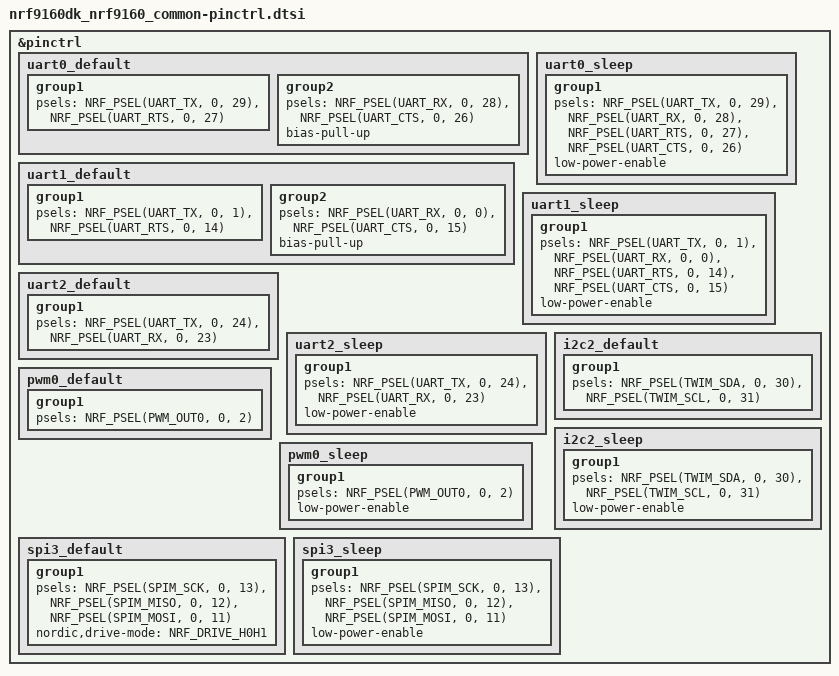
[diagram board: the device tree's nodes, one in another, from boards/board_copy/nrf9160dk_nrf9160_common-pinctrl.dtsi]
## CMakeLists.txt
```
cmake_minimum_required(VERSION 3.20.0)

list(APPEND BOARD_ROOT ${CMAKE_CURRENT_LIST_DIR})

# zephyr_library()
# zephyr_library_sources(board.c)

find_package(Zephyr REQUIRED)
project(my_zephyr_app)

target_include_directories(app PRIVATE inc/)

# add_subdirectory(drivers/sensor)
target_sources(app PRIVATE src/main.cpp drivers/sensor/led_sensor.c)
```

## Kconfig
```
menu "LED Subsystem"
  config APP_HEARTBEAT_PERIOD_MS
      int "Heartbeat period (ms)"
      default 500
      range 100 1000
      help
        Set the heartbeat period for the LED in milliseconds. This value determines how frequently the LED will blink to indicate that the application is running. Adjust this setting based on your application's requirements for visual feedback.
  config LED_SLEEP_TIME_MS
      int "LED sleep time (ms)"
      default 1000
      range 100 10000
      help
        Set the sleep time for the LED in milliseconds. This value determines how long the LED will remain on before turning off. Adjust this setting based on your application's requirements for visual feedback.
  
  menuconfig LED_ADVANCED
    bool "Advanced LED Options"
    default n


  if LED_ADVANCED

    config LED_BRIGHTNESS
        int "LED brightness (0-100)"
        default 100
        range 0 100

    config LED_FADE_DURATION_MS
        int "LED fade duration (ms)"
        default 500
        range 0 10000

    menu "Expert settings"

      config LED_DEBUG
          bool "Enable LED debugging"
          default n

      config LED_CUSTOM_PATTERN
          bool "Custom blink pattern"
          default n
    
    endmenu
  endif
    
endmenu
source "Kconfig.zephyr"
rsource "drivers/sensor/Kconfig"
```

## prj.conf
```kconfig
CONFIG_GPIO=y
CONFIG_LOG=y
CONFIG_LOG_MODE_IMMEDIATE=y
CONFIG_PWM=y

CONFIG_SENSOR=y
CONFIG_LED_SENSOR=y

CONFIG_SHELL=y
CONFIG_SHELL_BACKEND_SERIAL=y
CONFIG_SERIAL=y
CONFIG_CONSOLE=y
CONFIG_UART_CONSOLE=y
```

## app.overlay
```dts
/ {
    aliases {
        app-led = &led1;
    };

    led_sensor: led-sensor {
        compatible = "demo,led-sensor";
        status = "okay";
    };
};
```

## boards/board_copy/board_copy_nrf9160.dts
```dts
/*
 * Copyright (c) 2018-2020 Nordic Semiconductor ASA
 *
 * SPDX-License-Identifier: Apache-2.0
 */

/dts-v1/;
#include <nordic/nrf9160_sica.dtsi>
#include "nrf9160dk_nrf9160_common.dtsi"

/ {
	chosen {
		zephyr,sram = &sram0_s;
		zephyr,flash = &flash0;
		zephyr,code-partition = &slot0_partition;
		zephyr,sram-secure-partition = &sram0_s;
		zephyr,sram-non-secure-partition = &sram0_ns;
	};
};
```

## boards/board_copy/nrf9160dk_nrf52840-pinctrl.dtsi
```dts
/*
 * Copyright (c) 2022 Nordic Semiconductor
 * SPDX-License-Identifier: Apache-2.0
 */

&pinctrl {
	uart0_default: uart0_default {
		group1 {
			psels = <NRF_PSEL(UART_TX, 0, 5)>,
				<NRF_PSEL(UART_RTS, 0, 7)>;
		};

		group2 {
			psels = <NRF_PSEL(UART_RX, 0, 3)>,
				<NRF_PSEL(UART_CTS, 1, 8)>;
			bias-pull-up;
		};
	};

	uart0_sleep: uart0_sleep {
		group1 {
			psels = <NRF_PSEL(UART_TX, 0, 5)>,
				<NRF_PSEL(UART_RX, 0, 3)>,
				<NRF_PSEL(UART_RTS, 0, 7)>,
				<NRF_PSEL(UART_CTS, 1, 8)>;
			low-power-enable;
		};
	};
};
```

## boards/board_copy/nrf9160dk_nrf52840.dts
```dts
/*
 * Copyright (c) 2018-2020 Nordic Semiconductor ASA
 * Copyright (c) 2017 Linaro Limited
 *
 * SPDX-License-Identifier: Apache-2.0
 */

/dts-v1/;
#include <nordic/nrf52840_qiaa.dtsi>
#include <nordic/nrf52840_partition.dtsi>
#include "nrf9160dk_nrf52840-pinctrl.dtsi"

/ {
	model = "Nordic nRF9160 DK NRF52840";
	compatible = "nordic,nrf9160-dk-nrf52840";

	chosen {
		zephyr,console = &uart0;
		zephyr,shell-uart = &uart0;
		zephyr,uart-mcumgr = &uart0;
		zephyr,bt-mon-uart = &uart0;
		zephyr,ieee802154 = &ieee802154;
	};

	interface_to_nrf9160: gpio-interface {
		compatible = "nordic,nrf9160dk-nrf52840-interface";
		#gpio-cells = <2>;
		gpio-map-mask = <0xf 0>;
		gpio-map-pass-thru = <0 0xffffffff>;
		gpio-map = <0 0 &gpio0 17 0>,
			   <1 0 &gpio0 20 0>,
			   <2 0 &gpio0 15 0>,
			   <3 0 &gpio0 22 0>,
			   <4 0 &gpio1  4 0>,
			   <5 0 &gpio1  2 0>,
			   <6 0 &gpio1 13 0>,
			   <7 0 &gpio1 11 0>,
			   <8 0 &gpio1 15 0>;
	};

	reset_input: gpio-reset {
		compatible = "nordic,nrf9160dk-nrf52840-reset";
		/*
		 * This line is specified as active high for compatibility
		 * with the previously used Kconfig-based configuration.
		 */
		gpios = <&interface_to_nrf9160 5
			(GPIO_PULL_DOWN | GPIO_ACTIVE_HIGH)>;
		status = "disabled";
	};

	board-control {
		vcom0_pins_routing: switch-nrf91-uart1 {
			compatible = "nordic,nrf9160dk-optional-routing";
			control-gpios = <&gpio1 14 GPIO_ACTIVE_LOW>;
			status = "okay";
		};

		vcom2_pins_routing: switch-nrf91-uart2 {
			compatible = "nordic,nrf9160dk-optional-routing";
			/*
			 * Two pins (P1.12 and P0.12) need to be driven for
			 * this switch.
			 */
			control-gpios = <&gpio1 12 GPIO_ACTIVE_HIGH>,
					<&gpio0 12 GPIO_ACTIVE_HIGH>;
			status = "okay";
		};

		led1_pin_routing: switch-nrf91-led1 {
			compatible = "nordic,nrf9160dk-optional-routing";
			control-gpios = <&gpio1 5 GPIO_ACTIVE_LOW>;
			status = "okay";
		};

		led2_pin_routing: switch-nrf91-led2 {
			compatible = "nordic,nrf9160dk-optional-routing";
			control-gpios = <&gpio1 7 GPIO_ACTIVE_LOW>;
			status = "okay";
		};

		led3_pin_routing: switch-nrf91-led3 {
			compatible = "nordic,nrf9160dk-optional-routing";
			control-gpios = <&gpio1 1 GPIO_ACTIVE_LOW>;
			status = "okay";
		};

		led4_pin_routing: switch-nrf91-led4 {
			compatible = "nordic,nrf9160dk-optional-routing";
			control-gpios = <&gpio1 3 GPIO_ACTIVE_LOW>;
			status = "okay";
		};

		switch1_pin_routing: switch-nrf91-switch1 {
			compatible = "nordic,nrf9160dk-optional-routing";
			control-gpios = <&gpio1 9 GPIO_ACTIVE_LOW>;
			status = "okay";
		};

		switch2_pin_routing: switch-nrf91-switch2 {
			compatible = "nordic,nrf9160dk-optional-routing";
			control-gpios = <&gpio0 8 GPIO_ACTIVE_LOW>;
			status = "okay";
		};

		button1_pin_routing: switch-nrf91-button1 {
			compatible = "nordic,nrf9160dk-optional-routing";
			control-gpios = <&gpio0 6 GPIO_ACTIVE_LOW>;
			status = "okay";
		};

		button2_pin_routing: switch-nrf91-button2 {
			compatible = "nordic,nrf9160dk-optional-routing";
			control-gpios = <&gpio0 26 GPIO_ACTIVE_LOW>;
			status = "okay";
		};

		nrf_interface_pins_0_2_routing: switch-nrf-if0-2-ctrl {
			compatible = "nordic,nrf9160dk-optional-routing";
			control-gpios = <&gpio0 13 GPIO_ACTIVE_HIGH>;
			status = "disabled";
		};

		nrf_interface_pins_3_5_routing: switch-nrf-if3-5-ctrl {
			compatible = "nordic,nrf9160dk-optional-routing";
			control-gpios = <&gpio0 24 GPIO_ACTIVE_HIGH>;
			status = "disabled";
		};

		nrf_interface_pins_6_8_routing: switch-nrf-if6-8-ctrl {
			compatible = "nordic,nrf9160dk-optional-routing";
			control-gpios = <&gpio1 10 GPIO_ACTIVE_HIGH>;
			status = "disabled";
		};
	};

	aliases {
		watchdog0 = &wdt0;
	};
};

&reg1 {
	regulator-initial-mode = <NRF5X_REG_MODE_DCDC>;
};

&uicr {
	gpio-as-nreset;
};

&gpiote {
	status = "okay";
};

&gpio0 {
	status = "okay";
};

&gpio1 {
	status = "okay";
};

/* The nRF52840 SoC does not have any connection to the any of the LEDs,
 * buttons, switches and Arduino pin headers on the nRF9160 DK board.
 */

&uart0 {
	compatible = "nordic,nrf-uarte";
	current-speed = <115200>;
	status = "okay";
	pinctrl-0 = <&uart0_default>;
	pinctrl-1 = <&uart0_sleep>;
	pinctrl-names = "default", "sleep";
};

&ieee802154 {
	status = "okay";
};
```

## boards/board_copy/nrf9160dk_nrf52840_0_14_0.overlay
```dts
/*
 * Copyright (c) 2021 Nordic Semiconductor ASA
 *
 * SPDX-License-Identifier: Apache-2.0
 */

/ {
	board-control {
		nrf_interface_pin_9_routing: switch-nrf-if9-ctrl {
			compatible = "nordic,nrf9160dk-optional-routing";
			control-gpios = <&gpio0 16 GPIO_ACTIVE_HIGH>;
			status = "disabled";
		};

		io_expander_pins_routing: switch-io-exp-en {
			compatible = "nordic,nrf9160dk-optional-routing";
			control-gpios = <&gpio0 14 GPIO_ACTIVE_HIGH>;
			status = "disabled";
		};

		external_flash_pins_routing: switch-ext-mem-ctrl {
			compatible = "nordic,nrf9160dk-optional-routing";
			control-gpios = <&gpio0 19 GPIO_ACTIVE_HIGH>;
			status = "okay";
		};
	};
};

&interface_to_nrf9160 {
	gpio-map = <0 0 &gpio0 17 0>,
		   <1 0 &gpio0 20 0>,
		   <2 0 &gpio0 15 0>,
		   <3 0 &gpio0 22 0>,
		   <4 0 &gpio1  4 0>,
		   <5 0 &gpio1  2 0>,
		   <6 0 &gpio1 13 0>,
		   <7 0 &gpio1 11 0>,
		   <8 0 &gpio1 15 0>,
		   /* New signal added in this revision (0.14.0). */
		   <9 0 &gpio0 18 0>; /* nReset */
};

&vcom2_pins_routing {
	/* No need to drive P0.12 together with P1.12 in this board revision. */
	control-gpios = <&gpio1 12 GPIO_ACTIVE_HIGH>;
};

&reset_input {
	/* By default use the dedicated connection to the nRESET (P0.18) pin. */
	gpios = <&interface_to_nrf9160 9 (GPIO_PULL_UP | GPIO_ACTIVE_LOW)>;
};
```

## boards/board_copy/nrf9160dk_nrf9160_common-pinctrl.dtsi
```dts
/*
 * Copyright (c) 2022 Nordic Semiconductor
 * SPDX-License-Identifier: Apache-2.0
 */

&pinctrl {
	uart0_default: uart0_default {
		group1 {
			psels = <NRF_PSEL(UART_TX, 0, 29)>,
				<NRF_PSEL(UART_RTS, 0, 27)>;
		};

		group2 {
			psels = <NRF_PSEL(UART_RX, 0, 28)>,
				<NRF_PSEL(UART_CTS, 0, 26)>;
			bias-pull-up;
		};
	};

	uart0_sleep: uart0_sleep {
		group1 {
			psels = <NRF_PSEL(UART_TX, 0, 29)>,
				<NRF_PSEL(UART_RX, 0, 28)>,
				<NRF_PSEL(UART_RTS, 0, 27)>,
				<NRF_PSEL(UART_CTS, 0, 26)>;
			low-power-enable;
		};
	};

	uart1_default: uart1_default {
		group1 {
			psels = <NRF_PSEL(UART_TX, 0, 1)>,
				<NRF_PSEL(UART_RTS, 0, 14)>;
		};

		group2 {
			psels = <NRF_PSEL(UART_RX, 0, 0)>,
				<NRF_PSEL(UART_CTS, 0, 15)>;
			bias-pull-up;
		};
	};

	uart1_sleep: uart1_sleep {
		group1 {
			psels = <NRF_PSEL(UART_TX, 0, 1)>,
				<NRF_PSEL(UART_RX, 0, 0)>,
				<NRF_PSEL(UART_RTS, 0, 14)>,
				<NRF_PSEL(UART_CTS, 0, 15)>;
			low-power-enable;
		};
	};

	uart2_default: uart2_default {
		group1 {
			psels = <NRF_PSEL(UART_TX, 0, 24)>,
				<NRF_PSEL(UART_RX, 0, 23)>;
		};
	};

	uart2_sleep: uart2_sleep {
		group1 {
			psels = <NRF_PSEL(UART_TX, 0, 24)>,
				<NRF_PSEL(UART_RX, 0, 23)>;
			low-power-enable;
		};
	};

	i2c2_default: i2c2_default {
		group1 {
			psels = <NRF_PSEL(TWIM_SDA, 0, 30)>,
				<NRF_PSEL(TWIM_SCL, 0, 31)>;
		};
	};

	i2c2_sleep: i2c2_sleep {
		group1 {
			psels = <NRF_PSEL(TWIM_SDA, 0, 30)>,
				<NRF_PSEL(TWIM_SCL, 0, 31)>;
			low-power-enable;
		};
	};

	pwm0_default: pwm0_default {
		group1 {
			psels = <NRF_PSEL(PWM_OUT0, 0, 2)>;
		};
	};

	pwm0_sleep: pwm0_sleep {
		group1 {
			psels = <NRF_PSEL(PWM_OUT0, 0, 2)>;
			low-power-enable;
		};
	};

	spi3_default: spi3_default {
		group1 {
			psels = <NRF_PSEL(SPIM_SCK, 0, 13)>,
				<NRF_PSEL(SPIM_MISO, 0, 12)>,
				<NRF_PSEL(SPIM_MOSI, 0, 11)>;
			nordic,drive-mode = <NRF_DRIVE_H0H1>;
		};
	};

	spi3_sleep: spi3_sleep {
		group1 {
			psels = <NRF_PSEL(SPIM_SCK, 0, 13)>,
				<NRF_PSEL(SPIM_MISO, 0, 12)>,
				<NRF_PSEL(SPIM_MOSI, 0, 11)>;
			low-power-enable;
		};
	};
};
```

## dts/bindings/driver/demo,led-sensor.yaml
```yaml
description: This binding describes a simple LED sensor device that can be controlled via GPIO.
compatible: demo,led-sensor
include: sensor-device.yaml
```

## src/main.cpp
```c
#include <zephyr/drivers/gpio.h>
#include <zephyr/drivers/sensor.h>
#include <zephyr/kernel.h>
#include <zephyr/drivers/led.h>
#include <zephyr/logging/log.h>

#include <zephyr/sys/printk.h>

#include <zephyr/device.h>
#include <zephyr/shell/shell.h>

#include "led_sensor.h"


#ifndef CONFIG_LED_SLEEP_TIME_MS
#define CONFIG_LED_SLEEP_TIME_MS 1000
#endif

#ifndef CONFIG_LED_BRIGHTNESS
#define CONFIG_LED_BRIGHTNESS 50
#endif

#ifndef CONFIG_APP_HEARTBEAT_PERIOD_MS
#define CONFIG_APP_HEARTBEAT_PERIOD_MS 500
#endif

// #define APP_LED DT_ALIAS(app_led)
// static const struct gpio_dt_spec app_led = GPIO_DT_SPEC_GET(APP_LED, gpios);

// #define LED_NODE DT_ALIAS(led0)
// static const struct gpio_dt_spec led = GPIO_DT_SPEC_GET(LED_NODE, gpios);

// #define PWM_LED_NODE DT_NODELABEL(pwm_led0)
// static const struct led_dt_spec led_pwm = LED_DT_SPEC_GET(LED_NODE);




LOG_MODULE_REGISTER(main, LOG_LEVEL_INF);


static const struct device *led_sensor_dev = DEVICE_DT_GET(DT_NODELABEL(led_sensor));

static int cmd_sensor_fetch(const struct shell *shell, size_t argc, char **argv)
{
    struct sensor_value val;
    int ret;

    if (!device_is_ready(led_sensor_dev))
    {
        shell_error(shell, "LED sensor device not ready");
        return -ENODEV;
    }

    ret = sensor_sample_fetch(led_sensor_dev);
    if (ret < 0)
    {
        shell_error(shell, "Failed to fetch sample: %d", ret);
        return ret;
    }

    ret = sensor_channel_get(led_sensor_dev, SENSOR_CHAN_ALL, &val);
    if (ret < 0)
    {
        shell_error(shell, "Failed to get channel data: %d", ret);
        return ret;
    }

    shell_print(shell, "Sample count: %d", val.val1);

    return 0;
}

static int cmd_sensor_read(const struct shell *shell, size_t argc, char **argv)
{
    struct sensor_value val;
    int ret;

    if (!device_is_ready(led_sensor_dev))
    {
        shell_error(shell, "LED sensor device not ready");
        return -ENODEV;
    }

    ret = sensor_channel_get(led_sensor_dev, SENSOR_CHAN_ALL, &val);
    if (ret < 0)
    {
        shell_error(shell, "Failed to get channel data: %d", ret);
        return ret;
    }

    shell_print(shell, "Sample count: %d", val.val1);

    return 0;
}

static int cmd_sensor_info(const struct shell *shell, size_t argc, char **argv)
{
    shell_print(shell, "LED Sensor Device: %s", led_sensor_dev->name);
    shell_print(shell, "Ready: %s", device_is_ready(led_sensor_dev) ? "Yes" : "No");
    return 0;
}

static int cmd_sensor_set(const struct shell *shell, size_t argc, char **argv)
{
    if (argc < 2)
    {
        shell_error(shell, "Usage: sensor set <count>");
        return -EINVAL;
    }

    uint32_t count = strtoul(argv[1], NULL, 10);
    int ret = led_sensor_set_sample_count(led_sensor_dev, count);
    if (ret < 0)
    {
        shell_error(shell, "Failed to set sample count: %d", ret);
        return ret;
    }

    shell_print(shell, "Sample count set to: %d", count);
    return 0;
}


SHELL_STATIC_SUBCMD_SET_CREATE(sensor_cmds,
    SHELL_CMD(fetch, NULL, "Fetch a new sample from the LED sensor", cmd_sensor_fetch),
    SHELL_CMD(read, NULL, "Read the last fetched sample from the LED sensor", cmd_sensor_read),
    SHELL_CMD(info, NULL, "Get information about the LED sensor device", cmd_sensor_info),
    SHELL_CMD(set, NULL, "Set the sample count for the LED sensor", cmd_sensor_set),
    SHELL_SUBCMD_SET_END
);

SHELL_CMD_REGISTER(sensor, &sensor_cmds, "LED Sensor commands", NULL);

int main(void)
{
    // bool led_state = true;

    // if (!gpio_is_ready_dt(&app_led)) return 0;

    // if (gpio_pin_configure_dt(&app_led, GPIO_OUTPUT_ACTIVE) < 0) return 0;

    // while (1) {
    //     if (gpio_pin_toggle_dt(&app_led) < 0) return 0;

    //     led_state = !led_state;
    //     LOG_INF("LED state: %s", led_state ? "ON" : "OFF");
    //     k_msleep(CONFIG_APP_HEARTBEAT_PERIOD_MS);
    // }
    // LOG_INF("Hello, Zephyr!");

    // const struct device *led_sensor_dev = DEVICE_DT_GET(DT_NODELABEL(led_sensor));

    // struct sensor_value val;
    // int ret;

    // if (!device_is_ready(led_sensor_dev))
    // {
    //     LOG_ERR("LED sensor device not ready");
    //     return 0;
    // }

    // ret = led_sensor_set_sample_count(led_sensor_dev, 10U);

    // if (ret < 0) {
    //     LOG_ERR("Failed to update sample count: %d", ret);
    //     return 0;
    // }

    // while(1)
    // {
    //     ret = sensor_sample_fetch(led_sensor_dev);
    //     if (ret < 0)
    //     {
    //         LOG_ERR("Failed to fetch sample: %d", ret);
    //         return 0;
    //     }

    //     ret = sensor_channel_get(led_sensor_dev, SENSOR_CHAN_ALL, &val);
    //     if (ret < 0)
    //     {
    //         LOG_ERR("Failed to get channel data: %d", ret);
    //         return 0;
    //     }

    //     k_msleep(CONFIG_APP_HEARTBEAT_PERIOD_MS);
    // }
}
```

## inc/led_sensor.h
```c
#ifndef LED_SENSOR_H
#define LED_SENSOR_H

#include <stdint.h>
#include <zephyr/device.h>

#ifdef __cplusplus
extern "C" {
#endif

int led_sensor_set_sample_count(const struct device *dev, uint32_t count);

#ifdef __cplusplus
}
#endif

#endif /* LED_SENSOR_H */
```
